# GAP8 register map
Vendor: GreenWaves Technologies SAS; Series: GAP8; File version: 1.3.1
CPU: other r1p0, little endian, MPU, no FPU, I-cache, DTCM, false interrupt priority bits
Registers are 32-bit, read-write, reset 0x0 unless marked. A register's access mark holds for its fields unless they carry their own. Offsets are from the block's base; [hi:lo] are bit positions; {n}, {i} and the like mark numbered series; 'fields as' and 'values as' point back to an identical list.

## cl_core0 — Cluster Core 0 (Debug Unit)
Base 0x10300000
Same registers: cl_core1 0x10308000, cl_core2 0x10310000, cl_core3 0x10318000, cl_core4 0x10320000, cl_core5 0x10328000, cl_core6 0x10330000, cl_core7 0x10338000
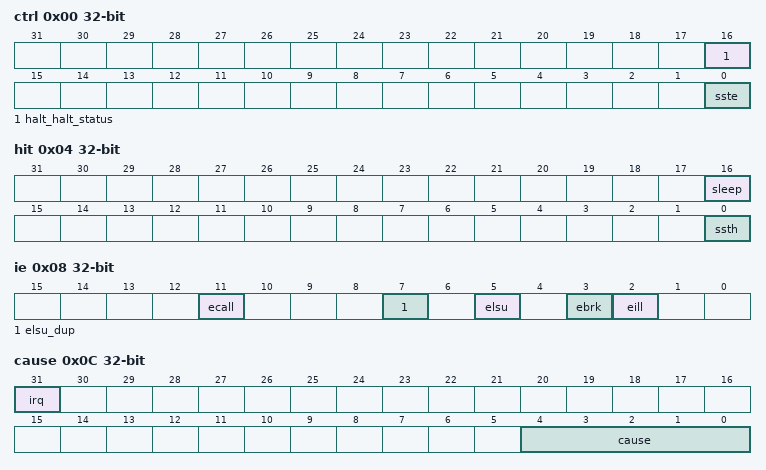
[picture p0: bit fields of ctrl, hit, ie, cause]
0x00 ctrl — Debug control configuration register.
  [16] halt_halt_status — Debug mode configuration bitfield Debug mode status bitfield
    on write: 0=exits_debug_mode (set to exits debug mode); 1=enters debug mode breaking code execution | on read: 0=running_mode (set to running mode); 1=debug_mode (set to debug mode)
  [0] sste — Single step mode configuration bitfield
    0=disabled (feature is disabled); 1=enabled (feature is enabled)
0x04 hit — Debug hit status register.
  [16] sleep ro — Sleep mode status bitfield
    on read: 0=running (core is in running state); 1=sleeping – core is in sleeping state and waits for en event to wake up
  [0] ssth — Single step hit status bitfield Sticky bit that must be cleared by external debugger.
    0=disabled (single step mode disabled); 1=enabled – single step mode enabled
0x08 ie — Debug exception trap enable configuration register.
  [11] ecall — Environment call trap configuration bitfield
    0=normal exception behavior mode; 1=cause_trap (exception causes trap and core switch into debug mode)
  [7] elsu_dup — Load/store access fault trap configuration bitfield This bitfield is duplicates the ELSU bitfield.
    0=normal exception behavior mode; 1=cause trap – exception causes trap and core switch into debug mode
  [5] elsu — Load/store access fault trap configuration bitfield
    values as elsu_dup
  [3] ebrk — Environment break trap configuration bitfield
    values as elsu_dup
  [2] eill — Illegal instruction trap configuration bitfield
    values as elsu_dup
0x0C cause ro — Debug trap cause status register.
  [31] irq — Core in debug mode due to interrupt trap status bitfield
    on read: 0=false (feature is set to false); 1=true (feature is set to true)
  [4:0] cause — Exception ID bitfield. If IRQ is 1'b1 contains interrupt number otherwise - 6'h0b sigecall - eCall machine mode - 6'h1f sigstop - core was halted by an external signal
    on read: 2=sigill (Illegal Instruction); 3=sigtrap (breakpoint); 11=sigecall (eCall user mode)
{0x400+4i} gpr{i} (i=0..31) — Core general purpose register {i} value register.
  [31:0] gpr{i} — General purpose register {i} value bitfield.
0x2000 npc — Debug next program counter value register.
  [31:0] npc — Next program counter value bitfield.
0x2004 ppc ro — Debug previous program counter value register.
  [31:0] ppc — Previous program counter value bitfield.
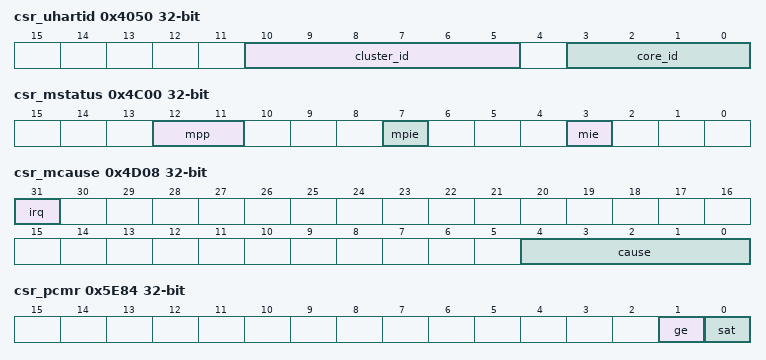
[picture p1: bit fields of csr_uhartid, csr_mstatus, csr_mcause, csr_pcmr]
0x4050 csr_uhartid ro — Core CSR user privilege mode hardware thread ID status register.
  [10:5] cluster_id — Cluster ID value bitfield.
  [3:0] core_id — RI5CY core ID value bitfield.
0x4C00 csr_mstatus — Core CSR machine status value register.
  [12:11] mpp — Hardwired to 2'b11.
  [7] mpie — Machine privilege mode previous interrupt enable value bitfield. When an interrupis encountered, MPIE will store the value existing in MIE. When mret instruction is executed, the value of MPIE is restored into MIE.
  [3] mie — Machine privilege mode interrupt enable configuration bitfield
    values as ctrl.sste
0x4C14 csr_mtvec — Core CSR machine vector-trap base address value register.
  [31:8] mtvec — Machine trap-vector base address value bitfield.
0x4D04 csr_mepc — Core CSR machine exception program counter value register.
  [31:0] mepc — Machine exception program counter value bitfield. When an exception is encountered, the current program counter is saved in MEPC, and the core jumps to the exception address. When an mret instruction is executed, the value from MEPC is restored to the current program counter.
0x4D08 csr_mcause — Core CSR machine trap cause value register.
  [31] irq ro — Core triggered an exception due to interrupt status bitfield
    values as cause.irq
  [4:0] cause ro — Exception ID bitfield. If IRQ is 1'b1 contains interrupt number otherwise - 6'h0b sigecall - eCall machine mode - 6'h1f sigstop - core was halted by an external signal
    values as cause.cause
0x5E00 csr_pccr — Core CSR performance counter counter register.
  [31:0] pccr — Program counter counter value bitfield.
0x5E80 csr_pcer — Core CSR performance counter enable configuration register.
  [20:0] pcer — See documentation on [RI5CY core](<https://pulp-platform.org//wp-content/uploads/2017/11/ri5cy_user_manual.pdf>) for details.
0x5E84 csr_pcmr — Core CSR performance counter mode configuration register.
  [1] ge — Performance counter activation configuration bitfield
    values as ctrl.sste
  [0] sat — Performance counter saturation mode configuration bitfield
    0=wrap-around mode; 1=saturation – saturation mode
0x5EC0 csr_hwlp0s — Core CSR hardware loop 0 start configuration register.
  [31:0] start — Hardware loop start address configuration bitfield.
0x5EC4 csr_hwlp0e — Core CSR hardware loop 0 end configuration register.
  [31:0] end — Hardware loop end address configuration bitfield.
0x5EC8 csr_hwlp0c — Core CSR hardware loop 0 counter configuration register.
  [31:0] cnt — Hardware loop counter configuration bitfield.
0x5ED0 csr_hwlp1s — Core CSR hardware loop 1 start configuration register.
  [31:0] start — Hardware loop start address configuration bitfield.
0x5ED4 csr_hwlp1e — Core CSR hardware loop 1 end configuration register.
  [31:0] end — Hardware loop end address configuration bitfield.
0x5ED8 csr_hwlp1c — Core CSR hardware loop 1 counter configuration register.
  [31:0] cnt — Hardware loop counter configuration bitfield.
0x7040 csr_privlv ro — Cose CSR privilege level status register.
  [1:0] plev — Hardwired to 2'b11.
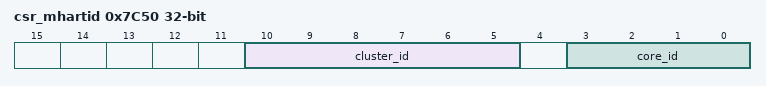
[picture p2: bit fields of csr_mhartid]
0x7C50 csr_mhartid ro — Core CSR machine privilege mode hardware thread ID status register.
  fields as csr_uhartid

## fc_core — FC Core 0 (Debug Unit)
Base 0x1B300000
Registers as cl_core0; these are added or differ:
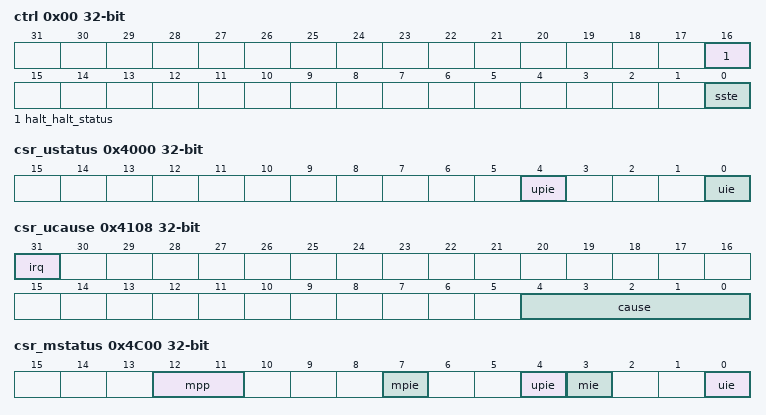
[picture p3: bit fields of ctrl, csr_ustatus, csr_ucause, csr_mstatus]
0x00 ctrl — Debug control configuration register.
  [16] halt_halt_status — Debug mode configuration bitfield Debug mode status bitfield
    on write: 0=exit_debug (exits debug mode); 1=enter debug – enters debug mode breaking code execution | on read: 0=running_mode (set to running mode); 1=debug_mode (set to debug mode)
  [0] sste — Single step mode configuration bitfield
    0=disabled (feature is disabled); 1=enabled (feature is enabled)
0x4000 csr_ustatus — Core CSR user status value register.
  [4] upie — User privilege mode previous interrupt enable value bitfield. When an interrupis encountered, UPIE will store the value existing in UIE. When uret instruction is executed, the value of UPIE is restored into UIE.
  [0] uie — User privilege mode interrupt enable configuration bitfield
    values as ctrl.sste
0x4014 csr_utvec — Core CSR user vector-trap base address value register.
  [31:8] utvec — Machine trap-vector base address value bitfield. When an exception is encountered, the core jumps to the corresponding handler using the content of the MTVEC as base address.
0x4104 csr_uepc — Core CSR user exception program counter value register.
  [31:0] uepc — Machine exception program counter value bitfield. When an exception is encountered, the current program counter is saved in MEPC, and the core jumps to the exception address. When an mret instruction is executed, the value from MEPC is restored to the current program counter.
0x4108 csr_ucause — Core CSR user trap cause value register.
  [31] irq ro — Core triggered an exception due to interrupt status bitfield
    on read: 0=false (feature is set to false); 1=true (feature is set to true)
  [4:0] cause ro — Exception ID bitfield.
0x4C00 csr_mstatus — Core CSR machine status value register.
  [12:11] mpp — Machine privilege mode previous privilege mode value bitfield
    0=user_mode (set to User mode); 3=machine_mode (set to Machine mode)
  [7] mpie — Machine privilege mode previous interrupt enable value bitfield. When an interrupis encountered, MPIE will store the value existing in MIE. When mret instruction is executed, the value of MPIE is restored into MIE.
  [4] upie — User privilege mode previous interrupt enable value bitfield. When an interrupis encountered, UPIE will store the value existing in UIE. When uret instruction is executed, the value of UPIE is restored into UIE.
  [3] mie — Machine privilege mode interrupt enable configuration bitfield
    values as ctrl.sste
  [0] uie — User privilege mode interrupt enable configuration bitfield
    values as ctrl.sste
0x4C14 csr_mtvec — Core CSR machine vector-trap base address value register.
  [31:8] mtvec — Machine trap-vector base address value bitfield. When an exception is encountered, the core jumps to the corresponding handler using the content of the MTVEC as base address.
0x7040 csr_privlv ro — Core CSR current privilege level status register.
  [1:0] plev — Current privilege level status bitfield
    on read: 0=user_mode (set to User mode); 3=machine_mode (set to Machine mode)

## Notices in the file
Copyright (c) 2017 GreenWaves Technologies SAS
All rights reserved.
Redistribution and use in source and binary forms, with or without
modification, are permitted provided that the following conditions are met:
1. Redistributions of source code must retain the above copyright notice,
this list of conditions and the following disclaimer.
2. Redistributions in binary form must reproduce the above copyright
notice, this list of conditions and the following disclaimer in the
documentation and/or other materials provided with the distribution.
3. Neither the name of GreenWaves Technologies SAS nor the names of its
contributors may be used to endorse or promote products derived from
this software without specific prior written permission.
THIS SOFTWARE IS PROVIDED BY THE COPYRIGHT HOLDERS AND CONTRIBUTORS "AS IS"
AND ANY EXPRESS OR IMPLIED WARRANTIES, INCLUDING, BUT NOT LIMITED TO, THE
IMPLIED WARRANTIES OF MERCHANTABILITY AND FITNESS FOR A PARTICULAR PURPOSE
ARE DISCLAIMED. IN NO EVENT SHALL THE COPYRIGHT OWNER OR CONTRIBUTORS BE
LIABLE FOR ANY DIRECT, INDIRECT, INCIDENTAL, SPECIAL, EXEMPLARY, OR
CONSEQUENTIAL DAMAGES (INCLUDING, BUT NOT LIMITED TO, PROCUREMENT OF
SUBSTITUTE GOODS OR SERVICES; LOSS OF USE, DATA, OR PROFITS; OR BUSINESS
INTERRUPTION) HOWEVER CAUSED AND ON ANY THEORY OF LIABILITY, WHETHER IN
CONTRACT, STRICT LIABILITY, OR TORT (INCLUDING NEGLIGENCE OR OTHERWISE)
ARISING IN ANY WAY OUT OF THE USE OF THIS SOFTWARE, EVEN IF ADVISED OF THE
POSSIBILITY OF SUCH DAMAGE.
